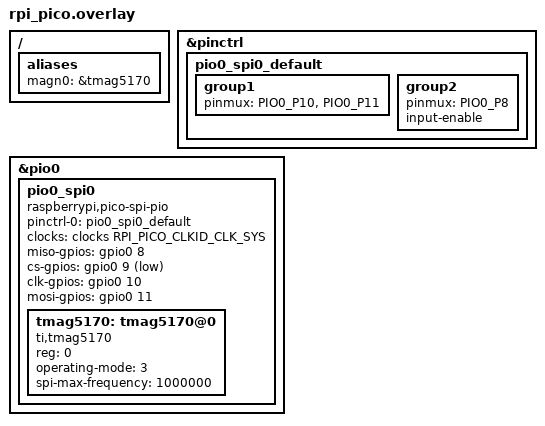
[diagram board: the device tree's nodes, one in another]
/ {
	aliases {
		magn0 = &tmag5170;
	};
};

&pinctrl {
	pio0_spi0_default: pio0_spi0_default {
		/* gpio 9 is used for chip select, not assigned to the PIO */
		group1 {
			pinmux = <PIO0_P10>, <PIO0_P11>;
		};
		group2 {
			pinmux = <PIO0_P8>;
			input-enable;
		};
	};
};

&pio0 {
	status = "okay";

	pio0_spi0: pio0_spi0 {
		pinctrl-0 = <&pio0_spi0_default>;
		pinctrl-names = "default";

		compatible = "raspberrypi,pico-spi-pio";
		status = "okay";
		#address-cells = <1>;
		#size-cells = <0>;
		clocks = <&clocks RPI_PICO_CLKID_CLK_SYS>;
		miso-gpios = <&gpio0 8 0>;
		cs-gpios = <&gpio0 9 GPIO_ACTIVE_LOW>;
		clk-gpios = <&gpio0 10 GPIO_ACTIVE_HIGH>;
		mosi-gpios = <&gpio0 11 GPIO_ACTIVE_HIGH>;
		tmag5170: tmag5170@0 {
			compatible = "ti,tmag5170";
			reg = <0>;
			operating-mode = <3>;
			spi-max-frequency = <1000000>; /* conservatively set to 1MHz */
		};
	};
};
